AUTOSAR XML (schema 00045)
package /MtsiAdapter
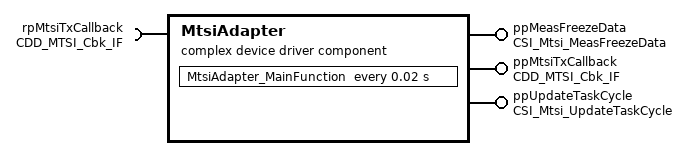
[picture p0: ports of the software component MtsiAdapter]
  complex device driver sw component type MtsiAdapter  # MTSI Adapter
    provide port ppMeasFreezeData: provided-interface=CSI_Mtsi_MeasFreezeData
    provide port ppMtsiTxCallback: provided-interface=CDD_MTSI_Cbk_IF
    provide port ppUpdateTaskCycle: provided-interface=CSI_Mtsi_UpdateTaskCycle
    require port rpMtsiTxCallback: required-interface=CDD_MTSI_Cbk_IF
    behavior MtsiAdapter_IB: handle-termination-and-restart=NO-SUPPORT
      operation invoked event CDD_MTSI_Callback_Event: start-on-event=CDD_MTSI_Callback, operation=ppMtsiTxCallback.CDD_MTSI_Callback
      init event InitEvent_MtsiAdapter_InitFunction: start-on-event=MtsiAdapter_InitFunction
      operation invoked event MeasFreezeData_Event: start-on-event=MtsiAdapter_MeasFreezeData, operation=ppMeasFreezeData.MeasFreezeData
      timing event TimingEvent_MtsiAdapter_MainFunction: start-on-event=MtsiAdapter_MainFunction, period=0.02
      operation invoked event UpdateTaskCycle_Event: start-on-event=MtsiAdapter_UpdateTaskCycle, operation=ppUpdateTaskCycle.UpdateTaskCycle
      5 x runnable:
        CDD_MTSI_Callback
          async call ascp_CDD_MTSI_Callback: operation=rpMtsiTxCallback.CDD_MTSI_Callback, timeout=0.0
        MtsiAdapter_InitFunction
        MtsiAdapter_MainFunction
        MtsiAdapter_MeasFreezeData
        MtsiAdapter_UpdateTaskCycle
  swc implementation MtsiAdapterImpl: programming-language=C, sw-version=0.0.1, vendor-id=0, behavior=MtsiAdapter_IB
    code-descriptors:
      code CodeGen: artifact-descriptors=[{short-label=SWSRC, category=SWSRC}, {short-label=SWHDR, category=SWHDR}]
    resource consumption Resource
      memory section CODE: sw-addrmethod=CODE
      memory section VAR_UNSPECIFIED: sw-addrmethod=VAR
